# RA4M1 register map
Vendor: Renesas Electronics Corporation; Series: RA4; File version: 1.2
CPU: CM4 r0p1, little endian, MPU, FPU, VTOR, 4 interrupt priority bits
Registers are 8-bit, read-write, reset 0x0 unless marked. A register's access mark holds for its fields unless they carry their own. Offsets are from the block's base; [hi:lo] are bit positions; {n}, {i} and the like mark numbered series; 'fields as' and 'values as' point back to an identical list.

## PORT1 — Port 1 Control Registers
Base 0x40040020
Same registers: PORT2 0x40040040, PORT3 0x40040060, PORT4 0x40040080
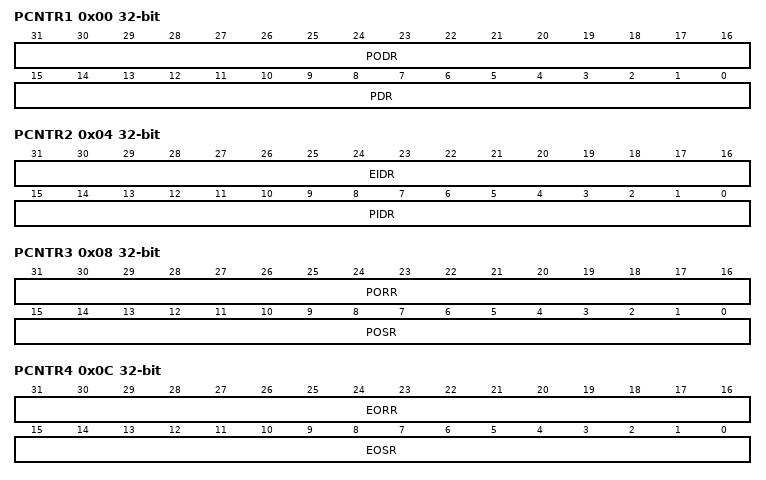
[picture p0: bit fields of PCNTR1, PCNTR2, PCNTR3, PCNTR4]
0x00 PCNTR1 32-bit — Port Control Register 1
  [31:16] PODR — Pmn Output Data
    0=Low output; 1=High output
  [15:0] PDR — Pmn Direction
    0=Input (functions as an input pin); 1=Output (functions as an output pin)
0x00 PODR 16-bit (alternate view of PCNTR1) — Output data register
  [15:0] PODR — Pmn Output Data
    0=Low output; 1=High output
0x02 PDR 16-bit (alternate view of PCNTR1) — Data direction register
  [15:0] PDR — Pmn Direction
    values as PCNTR1.PDR
0x04 PCNTR2 32-bit ro (reset mask 0xFFFF0000) — Port Control Register 2
  [31:16] EIDR — Pmn Event Input Data
    0=Low input; 1=High input
  [15:0] PIDR — Pmn Input Data
    0=Low input; 1=High input
0x04 EIDR 16-bit ro (alternate view of PCNTR2) — Event input data register
  [15:0] EIDR — Pmn Event Input Data
    0=Low input; 1=High input
0x06 PIDR 16-bit ro reset not defined (alternate view of PCNTR2) — Input data register
  [15:0] PIDR — Pmn Input Data
    0=Low input; 1=High input
0x08 PCNTR3 32-bit wo — Port Control Register 3
  [31:16] PORR — Pmn Output Reset
    0=No affect to output; 1=Low output
  [15:0] POSR — Pmn Output Set
    0=No affect to output; 1=High output
0x08 PORR 16-bit wo (alternate view of PCNTR3) — Output set register
  [15:0] PORR — Pmn Output Reset
    0=No affect to output; 1=Low output
0x0A POSR 16-bit wo (alternate view of PCNTR3) — Output reset register
  [15:0] POSR — Pmn Output Set
    0=No affect to output; 1=High output
0x0C PCNTR4 32-bit — Port Control Register 4
  [31:16] EORR — Pmn Event Output Reset
    0=No affect to output; 1=Low output
  [15:0] EOSR — Pmn Event Output Set
    0=No affect to output; 1=High output
0x0C EORR 16-bit (alternate view of PCNTR4) — Event output set register
  [15:0] EORR — Pmn Event Output Reset
    0=No affect to output; 1=Low output
0x0E EOSR 16-bit (alternate view of PCNTR4) — Event output reset register
  [15:0] EOSR — Pmn Event Output Set
    0=No affect to output; 1=High output

## PMISC — Miscellaneous Port Control Register
Base 0x40040D00
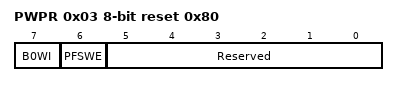
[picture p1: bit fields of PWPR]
0x03 PWPR reset 0x80 — Write-Protect Register
  [7] B0WI — PFSWE Bit Write Disable
    0=Writing to the PFSWE bit is enabled; 1=Writing to the PFSWE bit is disabled
  [6] PFSWE — PFS Register Write Enable
    0=Writing to the PFS register is disabled; 1=Writing to the PFS register is enabled
  [5:0] Reserved — These bits are read as 000000. The write value should be 000000.

## IWDT — Independent Watchdog Timer
Base 0x40044400
0x00 IWDTRR reset 0xFF — IWDT Refresh Register
  [7:0] IWDTRR — The counter is refreshed by writing 0x00 and then writing 0xFF to this register.
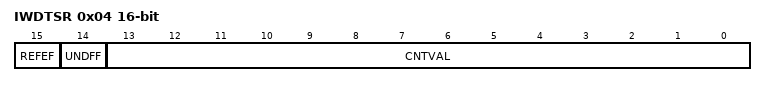
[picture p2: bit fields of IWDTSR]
0x04 IWDTSR 16-bit — IWDT Status Register
  [15] REFEF write-0-clears read-modifies — Refresh Error Flag
    0=Refresh error not occurred; 1=Refresh error occurred
  [14] UNDFF write-0-clears read-modifies — Underflow Flag
    0=Underflow not occurred; 1=Underflow occurred
  [13:0] CNTVAL ro — Counter Value Value counted by the counter

## KINT — Key Interrupt Function
Base 0x40080000
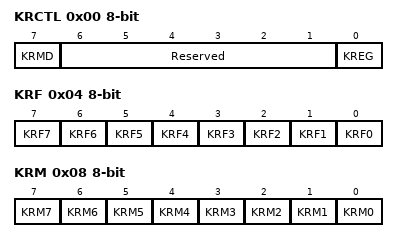
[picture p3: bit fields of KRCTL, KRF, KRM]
0x00 KRCTL — KEY Return Control Register
  [7] KRMD — Usage of Key Interrupt Flags(KR0 to KR7)
    0=Do not use key interrupt flags; 1=Use key interrupt flags
  [6:1] Reserved — These bits are read as 000000. The write value should be 000000.
  [0] KREG — Detection Edge Selection (KRF0 to KRF7)
    0=Falling edge; 1=Rising edge
0x04 KRF write-0-clears read-modifies — KEY Return Flag Register
  [all] fields
    0=No interrupt detected; 1=Interrupt detected
  [n] KRF{n} write-0-clears read-modifies (n=0..7) — Key interrupt flag {n}
0x08 KRM — KEY Return Mode Register
  [all] fields
    0=Does not detect key interrupt signal; 1=Detect key interrupt signal
  [n] KRM{n} (n=0..7) — Key interrupt mode control {n}
